VERSION ""

NS_ :

BS_:

BU_: Airbag_MQB BAP_Tester_MQB BMS_MQB Datenlogger_MQB Gateway_MQB Getriebe_DQ_Hybrid_MQB Getriebe_DQ_MQB LEH_MQB Motor_Diesel_MQB Motor_Hybrid_MQB Motor_Otto_MQB SAK_MQB Waehlhebel_MQB Vector__XXX l c i XXX

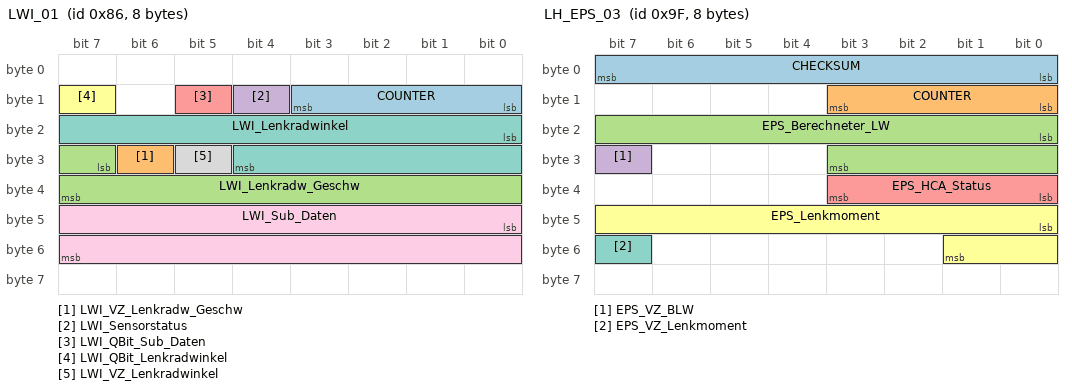
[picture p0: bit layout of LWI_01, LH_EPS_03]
BO_ 134 LWI_01: 8 XXX
 SG_ COUNTER : 8|4@1+ (1,0) [0|15] "" XXX
 SG_ LWI_VZ_Lenkradw_Geschw : 30|1@1+ (1,0) [0|1] "" XXX
 SG_ LWI_Lenkradw_Geschw : 31|9@1+ (5,0) [0|2500] "Unit_DegreOfArcPerSecon" XXX
 SG_ LWI_Sensorstatus : 12|1@1+ (1,0) [0|1] "" Airbag_MQB,Getriebe_DQ_Hybrid_MQB,Getriebe_DQ_MQB,Motor_Diesel_MQB,Motor_Hybrid_MQB,Motor_Otto_MQB
 SG_ LWI_QBit_Sub_Daten : 13|1@1+ (1,0) [0|1] "" Vector__XXX
 SG_ LWI_QBit_Lenkradwinkel : 15|1@1+ (1,0) [0|1] "" Airbag_MQB,Getriebe_DQ_Hybrid_MQB,Getriebe_DQ_MQB,Motor_Diesel_MQB,Motor_Hybrid_MQB,Motor_Otto_MQB
 SG_ LWI_Lenkradwinkel : 16|13@1+ (0.1,0) [0|800] "Unit_DegreOfArc" Airbag_MQB,Getriebe_DQ_Hybrid_MQB,Getriebe_DQ_MQB,Motor_Diesel_MQB,Motor_Hybrid_MQB,Motor_Otto_MQB
 SG_ LWI_VZ_Lenkradwinkel : 29|1@1+ (1,0) [0|1] "" Airbag_MQB,Getriebe_DQ_Hybrid_MQB,Getriebe_DQ_MQB,Motor_Diesel_MQB,Motor_Hybrid_MQB,Motor_Otto_MQB
 SG_ LWI_Sub_Daten : 40|16@1+ (1,0) [0|65535] "" Vector__XXX

BO_ 159 LH_EPS_03: 8 XXX
 SG_ CHECKSUM : 0|8@1+ (1,0) [0|255] "" XXX
 SG_ COUNTER : 8|4@1+ (1,0) [0|15] "" XXX
 SG_ EPS_Berechneter_LW : 16|12@1+ (0.15,0) [0|613.95] "Unit_DegreOfArc" XXX
 SG_ EPS_VZ_BLW : 31|1@1+ (1,0) [0|1] "" XXX
 SG_ EPS_HCA_Status : 32|4@1+ (1,0) [0|15] "" XXX
 SG_ EPS_Lenkmoment : 40|10@1+ (1,0) [0|8] "Unit_centiNewtoMeter" XXX
 SG_ EPS_VZ_Lenkmoment : 55|1@1+ (1,0) [0|1] "" XXX

BO_ 256 ESP_21: 8 XXX
 SG_ COUNTER : 8|4@1+ (1,0) [0|15] "" XXX
 SG_ ESP_Tastung_passiv : 49|1@1+ (1,0) [0|1] "" XXX

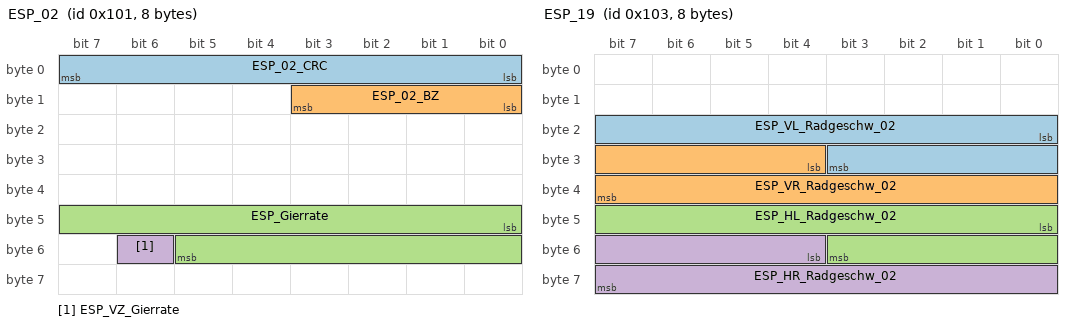
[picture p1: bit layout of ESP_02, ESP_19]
BO_ 257 ESP_02: 8 XXX
 SG_ ESP_02_CRC : 0|8@1+ (1,0) [0|255] "" XXX
 SG_ ESP_02_BZ : 8|4@1+ (1,0) [0|15] "" XXX
 SG_ ESP_Gierrate : 40|14@1+ (0.01,0) [0|163.82] "Unit_DegreOfArcPerSecon" XXX
 SG_ ESP_VZ_Gierrate : 54|1@1+ (1,0) [0|1] "" XXX

BO_ 259 ESP_19: 8 XXX
 SG_ ESP_VL_Radgeschw_02 : 16|12@1+ (0.1,0) [0|409.2] "Unit_KiloMeterPerHour" XXX
 SG_ ESP_VR_Radgeschw_02 : 28|12@1+ (0.1,0) [0|409.2] "Unit_KiloMeterPerHour" XXX
 SG_ ESP_HL_Radgeschw_02 : 40|12@1+ (0.1,0) [0|409.2] "Unit_KiloMeterPerHour" XXX
 SG_ ESP_HR_Radgeschw_02 : 52|12@1+ (0.1,0) [0|409.2] "Unit_KiloMeterPerHour" XXX

BO_ 261 Motor_20: 8 XXX
 SG_ COUNTER : 8|4@1+ (1,0) [0|15] "" XXX
 SG_ MO_Fahrpedalrohwert_01 : 48|8@1+ (0.4,0) [0|101.6] "Unit_PerCent" XXX

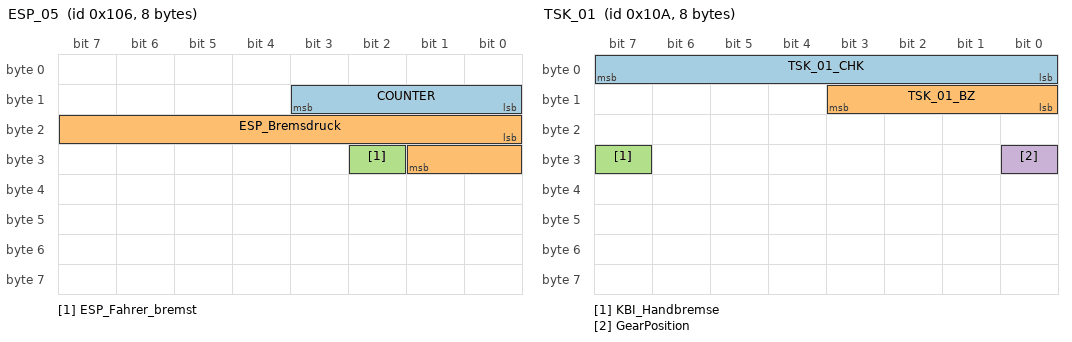
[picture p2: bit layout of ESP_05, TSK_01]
BO_ 262 ESP_05: 8 XXX
 SG_ COUNTER : 8|4@1+ (1,0) [0|15] "" XXX
 SG_ ESP_Bremsdruck : 16|10@1+ (0.3,-30) [-30|276.58978] "Unit_Bar" XXX
 SG_ ESP_Fahrer_bremst : 26|1@1+ (1,0) [0|1] "" XXX

BO_ 266 TSK_01: 8 XXX
 SG_ TSK_01_CHK : 0|8@1+ (1,0) [0|255] "" XXX
 SG_ TSK_01_BZ : 8|4@1+ (1,0) [0|15] "" XXX
 SG_ KBI_Handbremse : 31|1@1+ (1,0) [0|1] "" XXX
 SG_ GearPosition : 24|1@1+ (1,0) [0|1] "" XXX

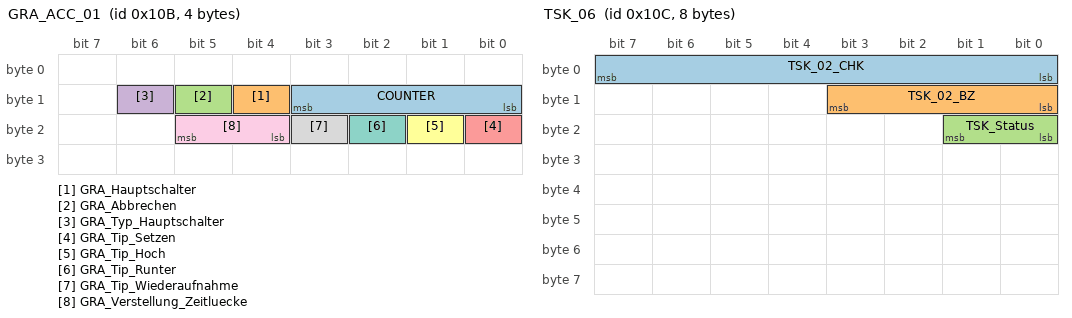
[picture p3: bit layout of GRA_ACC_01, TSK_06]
BO_ 267 GRA_ACC_01: 4 XXX
 SG_ COUNTER : 8|4@1+ (1,0) [0|15] "" XXX
 SG_ GRA_Hauptschalter : 12|1@1+ (1,0) [0|1] "" XXX
 SG_ GRA_Abbrechen : 13|1@1+ (1,0) [0|1] "" XXX
 SG_ GRA_Typ_Hauptschalter : 14|1@1+ (1,0) [0|1] "" XXX
 SG_ GRA_Tip_Setzen : 16|1@1+ (1,0) [0|1] "" XXX
 SG_ GRA_Tip_Hoch : 17|1@1+ (1,0) [0|1] "" XXX
 SG_ GRA_Tip_Runter : 18|1@1+ (1,0) [0|1] "" XXX
 SG_ GRA_Tip_Wiederaufnahme : 19|1@1+ (1,0) [0|1] "" XXX
 SG_ GRA_Verstellung_Zeitluecke : 20|2@1+ (1,0) [0|3] "" XXX

BO_ 268 TSK_06: 8 XXX
 SG_ TSK_02_CHK : 0|8@1+ (1,0) [0|255] "" XXX
 SG_ TSK_02_BZ : 8|4@1+ (1,0) [0|15] "" XXX
 SG_ TSK_Status : 16|2@1+ (1,0) [0|3] "" XXX

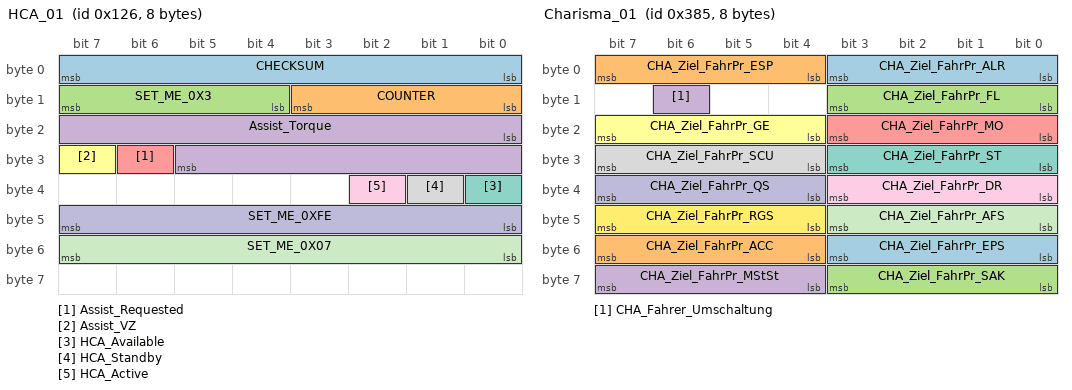
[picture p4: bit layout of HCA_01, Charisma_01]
BO_ 294 HCA_01: 8 XXX
 SG_ CHECKSUM : 0|8@1+ (1,0) [0|255] "" XXX
 SG_ COUNTER : 8|4@1+ (1,0) [0|15] "" XXX
 SG_ SET_ME_0X3 : 12|4@1+ (1,0) [0|15] "" XXX
 SG_ Assist_Torque : 16|14@1+ (1,0) [0|300] "Nm" XXX
 SG_ Assist_Requested : 30|1@1+ (1,0) [0|1] "" XXX
 SG_ Assist_VZ : 31|1@1+ (1,0) [0|1] "" XXX
 SG_ HCA_Available : 32|1@1+ (1,0) [0|1] "" XXX
 SG_ HCA_Standby : 33|1@1+ (1,0) [0|1] "" XXX
 SG_ HCA_Active : 34|1@1+ (1,0) [0|1] "" XXX
 SG_ SET_ME_0XFE : 40|8@1+ (1,0) [0|255] "" XXX
 SG_ SET_ME_0X07 : 48|8@1+ (1,0) [0|255] "" XXX

BO_ 779 Einheiten_01: 8 XXX
 SG_ KBI_MFA_v_Einheit_02 : 17|1@1+ (1,0) [0|1] "" XXX

BO_ 780 ACC_02: 8 XXX
 SG_ COUNTER : 8|4@1+ (1,0) [0|15] "" XXX
 SG_ ACC_Wunschgeschw : 12|10@1+ (0.32,0) [0.00|326.72] "Unit_KiloMeterPerHour" XXX

BO_ 867 Blinkmodi_02: 4 XXX
 SG_ Comfort_Signal_Left : 8|1@1+ (1,0) [0|1] "" XXX
 SG_ Comfort_Signal_Right : 9|1@1+ (1,0) [0|1] "" XXX

BO_ 1312 Airbag_02: 8 XXX
 SG_ AB_Gurtschloss_FA : 40|2@1+ (1,0) [0|3] "" XXX
 SG_ AB_Gurtschloss_BF : 42|2@1+ (1,0) [0|3] "" XXX

BO_ 1318 Gateway_72: 8 XXX
 SG_ BCM1_Rueckfahrlicht_Schalter : 32|1@1+ (1,0) [0|1] "" XXX
 SG_ ZV_FT_offen : 43|1@1+ (1,0) [0|1] "" XXX

BO_ 901 Charisma_01: 8 Gateway_MQB
 SG_ CHA_Ziel_FahrPr_ALR : 0|4@1+ (1,0) [0|15] "" Vector__XXX
 SG_ CHA_Ziel_FahrPr_ESP : 4|4@1+ (1,0) [0|15] "" Vector__XXX
 SG_ CHA_Ziel_FahrPr_FL : 8|4@1+ (1,0) [0|15] "" Vector__XXX
 SG_ CHA_Fahrer_Umschaltung : 14|1@1+ (1,0) [0|1] "" Airbag_MQB,Getriebe_DQ_Hybrid_MQB,Getriebe_DQ_MQB,Motor_Diesel_MQB,Motor_Hybrid_MQB,Motor_Otto_MQB,SAK_MQB
 SG_ CHA_Ziel_FahrPr_MO : 16|4@1+ (1,0) [0|15] "" Motor_Diesel_MQB,Motor_Hybrid_MQB,Motor_Otto_MQB
 SG_ CHA_Ziel_FahrPr_GE : 20|4@1+ (1,0) [0|15] "" Getriebe_DQ_Hybrid_MQB,Getriebe_DQ_MQB
 SG_ CHA_Ziel_FahrPr_ST : 24|4@1+ (1,0) [0|15] "" Vector__XXX
 SG_ CHA_Ziel_FahrPr_SCU : 28|4@1+ (1,0) [0|15] "" Vector__XXX
 SG_ CHA_Ziel_FahrPr_DR : 32|4@1+ (1,0) [0|15] "" Vector__XXX
 SG_ CHA_Ziel_FahrPr_QS : 36|4@1+ (1,0) [0|15] "" Vector__XXX
 SG_ CHA_Ziel_FahrPr_AFS : 40|4@1+ (1,0) [0|15] "" Vector__XXX
 SG_ CHA_Ziel_FahrPr_RGS : 44|4@1+ (1,0) [0|15] "" Airbag_MQB
 SG_ CHA_Ziel_FahrPr_EPS : 48|4@1+ (1,0) [0|15] "" Vector__XXX
 SG_ CHA_Ziel_FahrPr_ACC : 52|4@1+ (1,0) [0|15] "" Vector__XXX
 SG_ CHA_Ziel_FahrPr_SAK : 56|4@1+ (1,0) [0|15] "" SAK_MQB
 SG_ CHA_Ziel_FahrPr_MStSt : 60|4@1+ (1,0) [0|15] "" Vector__XXX

BO_ 1313 STH_01: 8 Gateway_MQB
 SG_ STH_Funk_ein : 0|1@1+ (1,0) [0|1] "" Vector__XXX
 SG_ STH_Funk_aus : 1|1@1+ (1,0) [0|1] "" Vector__XXX
 SG_ STH_Zusatzheizung : 2|1@1+ (1,0) [0|1] "" Vector__XXX
 SG_ STH_LED : 3|1@1+ (1,0) [0|1] "" Motor_Diesel_MQB,Motor_Hybrid_MQB,Motor_Otto_MQB
 SG_ STH_Pumpe_ein : 4|1@1+ (1,0) [0|1] "" Vector__XXX
 SG_ STH_Geblaese : 5|1@1+ (1,0) [0|1] "" Vector__XXX
 SG_ STH_EKP_Anst : 6|1@1+ (1,0) [0|1] "" Motor_Diesel_MQB,Motor_Hybrid_MQB,Motor_Otto_MQB
 SG_ STH_Start_folgt : 7|1@1+ (1,0) [0|1] "" Vector__XXX
 SG_ STH_Ventiloeffnungszeit : 8|6@1+ (1,0) [0|63] "Unit_Minut" Vector__XXX
 SG_ STH_Ventil_Status : 14|1@1+ (1,0) [0|1] "" Vector__XXX
 SG_ STH_Waermeeintrag : 16|6@1+ (1,0) [0|63] "" Vector__XXX
 SG_ STH_KVS : 24|13@1+ (1,0) [0|8191] "Unit_MilliLiter" Vector__XXX
 SG_ STH_Fehlerstatus : 37|3@1+ (1,0) [0|7] "" Vector__XXX
 SG_ STH_Heizleistung : 40|8@1+ (1,0) [0|255] "" Vector__XXX
 SG_ STH_Wassertemp : 48|8@1+ (0.75,-40) [-40|142.25] "Unit_DegreCelsi" Vector__XXX
 SG_ STH_Motorvorwaermung : 59|1@1+ (1,0) [0|1] "" Motor_Diesel_MQB,Motor_Hybrid_MQB,Motor_Otto_MQB
 SG_ STH_Servicemode : 60|1@1+ (1,0) [0|1] "" Vector__XXX
 SG_ STH_war_aktiv : 61|1@1+ (1,0) [0|1] "" Motor_Diesel_MQB,Motor_Hybrid_MQB,Motor_Otto_MQB
 SG_ STH_KVS_Ueberlauf : 62|1@1+ (1,0) [0|1] "" Vector__XXX
 SG_ STH_KD_Fehler : 63|1@1+ (1,0) [0|1] "" Vector__XXX

BO_ 919 LDW_02: 8 XXX
 SG_ LDW_Gong : 12|2@1+ (1,0) [0|3] ""  XXX
 SG_ LDW_SW_Warnung_links : 14|1@1+ (1,0) [0|1] ""  XXX
 SG_ LDW_SW_Warnung_rechts : 15|1@1+ (1,0) [0|1] ""  XXX
 SG_ LDW_Texte : 16|4@1+ (1,0) [0|15] ""  XXX
 SG_ LDW_Seite_DLCTLC : 20|1@1+ (1,0) [0|1] ""  XXX
 SG_ LDW_Lernmodus : 21|3@1+ (1,0) [0|7] ""  XXX
 SG_ LDW_Anlaufsp_VLR : 24|4@1+ (1,0) [0|15] ""  XXX
 SG_ LDW_Vib_Amp_VLR : 28|4@1+ (1,0) [0|15] ""  XXX
 SG_ LDW_Anlaufzeit_VLR : 32|4@1+ (1,0) [0|15] ""  XXX
 SG_ LDW_Lernmodus_rechts : 36|2@1+ (1,0) [0|3] ""  XXX
 SG_ LDW_Lernmodus_links : 38|2@1+ (1,0) [0|3] ""  XXX
 SG_ LDW_DLC : 40|8@1+ (0.01,-1.25) [-1.25|1.25] "Unit_Meter"  XXX
 SG_ LDW_TLC : 48|5@1+ (0.1,0) [0|3] "Unit_Secon"  XXX
 SG_ LDW_Warnung_links : 56|1@1+ (1,0) [0|1] ""  XXX
 SG_ LDW_Warnung_rechts : 57|1@1+ (1,0) [0|1] ""  XXX
 SG_ LDW_Codierinfo_fuer_VLR : 58|2@1+ (1,0) [0|3] ""  XXX
 SG_ LDW_Frontscheibenheizung_aktiv : 60|1@1+ (1,0) [0|1] ""  XXX
 SG_ LDW_Status_LED_gelb : 61|1@1+ (1,0) [0|1] ""  XXX
 SG_ LDW_Status_LED_gruen : 62|1@1+ (1,0) [0|1] ""  XXX

BO_ 783 SWA_01: 8 Gateway_MQB
 SG_ COUNTER : 8|4@1+ (1,0) [0|15] ""  Vector__XXX
 SG_ SWA_Anzeigen : 12|4@1+ (1,0) [0|15] ""  Kombi_D4
 SG_ SWA_Blindheit_erkannt : 16|1@1+ (1,0) [0|1] ""  Vector__XXX
 SG_ SWA_rel_Nichtverf : 17|1@1+ (1,0) [0|1] ""  Vector__XXX
 SG_ SWA_rel_Fehler : 18|1@1+ (1,0) [0|1] ""  Vector__XXX
 SG_ SWA_Sta_aktiv : 19|1@1+ (1,0) [0|1] ""  Vector__XXX
 SG_ SWA_Sta_passiv : 20|1@1+ (1,0) [0|1] ""  Vector__XXX
 SG_ SWA_Standziele_li : 24|1@1+ (1,0) [0|1] ""  Vector__XXX
 SG_ SWA_Kolonne_li : 25|1@1+ (1,0) [0|1] ""  Vector__XXX
 SG_ SWA_Infostufe_SWA_li : 26|1@1+ (1,0) [0|1] ""  Vector__XXX
 SG_ SWA_Warnung_SWA_li : 27|1@1+ (1,0) [0|1] ""  Vector__XXX
 SG_ SWA_Kolonne_mi : 33|1@1+ (1,0) [0|1] ""  Vector__XXX
 SG_ SWA_Standziele_re : 40|1@1+ (1,0) [0|1] ""  Vector__XXX
 SG_ SWA_Kolonne_re : 41|1@1+ (1,0) [0|1] ""  Vector__XXX
 SG_ SWA_Infostufe_SWA_re : 42|1@1+ (1,0) [0|1] ""  Vector__XXX
 SG_ SWA_Warnung_SWA_re : 43|1@1+ (1,0) [0|1] ""  Vector__XXX
 SG_ SWA_Gischtzaehler : 48|7@1+ (1,0) [0|100] "Unit_PerCent"  Vector__XXX
 SG_ SWA_KD_Fehler : 59|1@1+ (1,0) [0|1] ""  Vector__XXX

CM_ SG_ 134 LWI_Lenkradwinkel "Steering angle WITH variable ratio effect included";
CM_ SG_ 159 EPS_HCA_Status "Status of Heading Control Assist feature";
CM_ SG_ 159 EPS_Lenkmoment "Steering input by driver, torque";
CM_ SG_ 159 EPS_VZ_Lenkmoment "Steering input by driver, direction";
CM_ SG_ 159 EPS_Berechneter_LW "Raw steering angle, degrees";
CM_ SG_ 159 EPS_VZ_BLW "Raw steering angle, direction";
CM_ SG_ 173 COUNTERXX "Message not renamed to COUNTER because J533 rate-limiting makes it look like messages are being lost";
CM_ SG_ 294 SET_ME_0X3 "May be zero when sent by older cameras";
CM_ SG_ 294 SET_ME_0X07 "May be zero when sent by older cameras";
CM_ SG_ 294 SET_ME_0XFE "May be zero when sent by older cameras";
CM_ SG_ 294 Assist_Torque "Heading control input, torque";
CM_ SG_ 294 Assist_VZ "Heading control input, direction (sign)";
CM_ SG_ 294 HCA_Available "Must be 1 for steering rack to accept HCA commands";
CM_ SG_ 870 Hazard_Switch "Four-way flashers active";
CM_ SG_ 870 Comfort_Signal_Left "Comfort turn signal active, left";
CM_ SG_ 870 Comfort_Signal_Right "Comfort turn signal active, right";
CM_ SG_ 870 Left_Turn_Exterior_Bulb_1 "Probably front";
CM_ SG_ 870 Right_Turn_Exterior_Bulb_1 "Probably front";
CM_ SG_ 870 Left_Turn_Exterior_Bulb_2 "Probably rear";
CM_ SG_ 870 Right_Turn_Exterior_Bulb_2 "Probably rear";
CM_ SG_ 870 Fast_Send_Rate_Active "CAN message send rate";
CM_ SG_ 919 LDW_DLC "Probable DLC (distance to line crossing)";
CM_ SG_ 919 LDW_TLC "Probable TLC (time to line crossing)";
CM_ SG_ 919 LDW_Unknown "Might be a steering pressed / driver active flag";
CM_ SG_ 919 Alert_Message "Static table of alert messages to be invoked in the instrument cluster, some with or without beeps, 0 = no current message";
CM_ SG_ 919 LDW_Direction "Left/right indicator for DLC and TLC";
CM_ SG_ 919 Right_Lane_Status "Display brightness range, 0 = no lane, 3 = full brightness";
CM_ SG_ 919 Left_Lane_Status "Display brightness range, 0 = no lane, 3 = full brightness";
CM_ SG_ 919 Kombi_Lamp_Orange "Enables orange LDW light in instrument cluster";
CM_ SG_ 919 Kombi_Lamp_Green "Enables green LDW light in instrument cluster";
CM_ SG_ 780 Folgefahrt "Following another vehicle";
CM_ SG_ 780 SetAbstand "Set following distance";
CM_ SG_ 780 Abstand "Following distance";
CM_ SG_ 780 SetSpeed "ACC set speed";
CM_ SG_ 960 ZAS_Kl_15 "Indicates ignition on";
CM_ SG_ 1318 ZV_FT_offen "Door open signal was not found on extended CAN. Using the interior light state as indicator instead.";

VAL_ 159 EPS_HCA_Status 0 "disabled" 1 "initializing" 2 "fault" 3 "ready" 4 "rejected" 5 "active";
VAL_ 266 GearPosition 0 "D" 1 "N";
